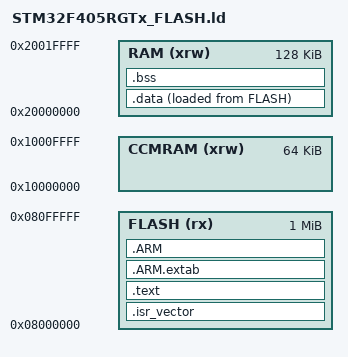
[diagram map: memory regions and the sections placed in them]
/*
 * STM32F405RGTx_FLASH.ld — Linker script for STM32F405RGT6
 *
 * Flash: 1 MB  @ 0x08000000
 * SRAM1: 128 KB @ 0x20000000
 * SRAM2: 64 KB  @ 0x10000000 (CCM — only accessible by CPU, not DMA)
 */

ENTRY(Reset_Handler)

_estack = 0x20020000;   /* Top of SRAM1 (128 KB) */

MEMORY
{
  FLASH (rx)  : ORIGIN = 0x08000000, LENGTH = 1024K
  RAM   (xrw) : ORIGIN = 0x20000000, LENGTH = 128K
  CCMRAM (xrw): ORIGIN = 0x10000000, LENGTH = 64K
}

SECTIONS
{
  .isr_vector :
  {
    . = ALIGN(4);
    KEEP(*(.isr_vector))
    . = ALIGN(4);
  } >FLASH

  .text :
  {
    . = ALIGN(4);
    *(.text)
    *(.text*)
    *(.rodata)
    *(.rodata*)
    KEEP(*(.init))
    KEEP(*(.fini))
    . = ALIGN(4);
    _etext = .;
  } >FLASH

  .ARM.extab : { *(.ARM.extab* .gnu.linkonce.armextab.*) } >FLASH
  .ARM        : { __exidx_start = .; *(.ARM.exidx*) __exidx_end = .; } >FLASH

  .data :
  {
    . = ALIGN(4);
    _sdata = .;
    *(.data)
    *(.data*)
    . = ALIGN(4);
    _edata = .;
  } >RAM AT>FLASH

  _sidata = LOADADDR(.data);

  .bss :
  {
    . = ALIGN(4);
    _sbss = .;
    *(.bss)
    *(.bss*)
    *(COMMON)
    . = ALIGN(4);
    _ebss = .;
  } >RAM

  /DISCARD/ :
  {
    libc.a ( * )
    libm.a ( * )
    libgcc.a ( * )
  }

  .ARM.attributes 0 : { *(.ARM.attributes) }
}
